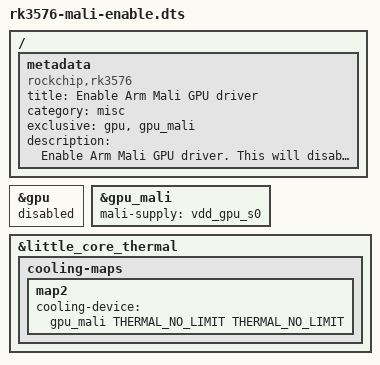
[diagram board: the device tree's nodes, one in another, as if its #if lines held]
/dts-v1/;
/plugin/;

#include <dt-bindings/thermal/thermal.h>
#include <generated/uapi/linux/version.h>

/ {
	metadata {
		title = "Enable Arm Mali GPU driver";
		compatible = "rockchip,rk3576";
		category = "misc";
		exclusive = "gpu", "gpu_mali";
		description = "Enable Arm Mali GPU driver.
This will disable opensource Panthor driver";
	};
};

&gpu {
	status = "disabled";
};

&gpu_mali {
	status = "okay";
	mali-supply = <&vdd_gpu_s0>;
};

#if LINUX_VERSION_CODE >= KERNEL_VERSION(6, 12, 0)
&little_core_thermal {
	cooling-maps {
		map2 {
			cooling-device = <&gpu_mali THERMAL_NO_LIMIT THERMAL_NO_LIMIT>;
		};
	};
};
#endif
